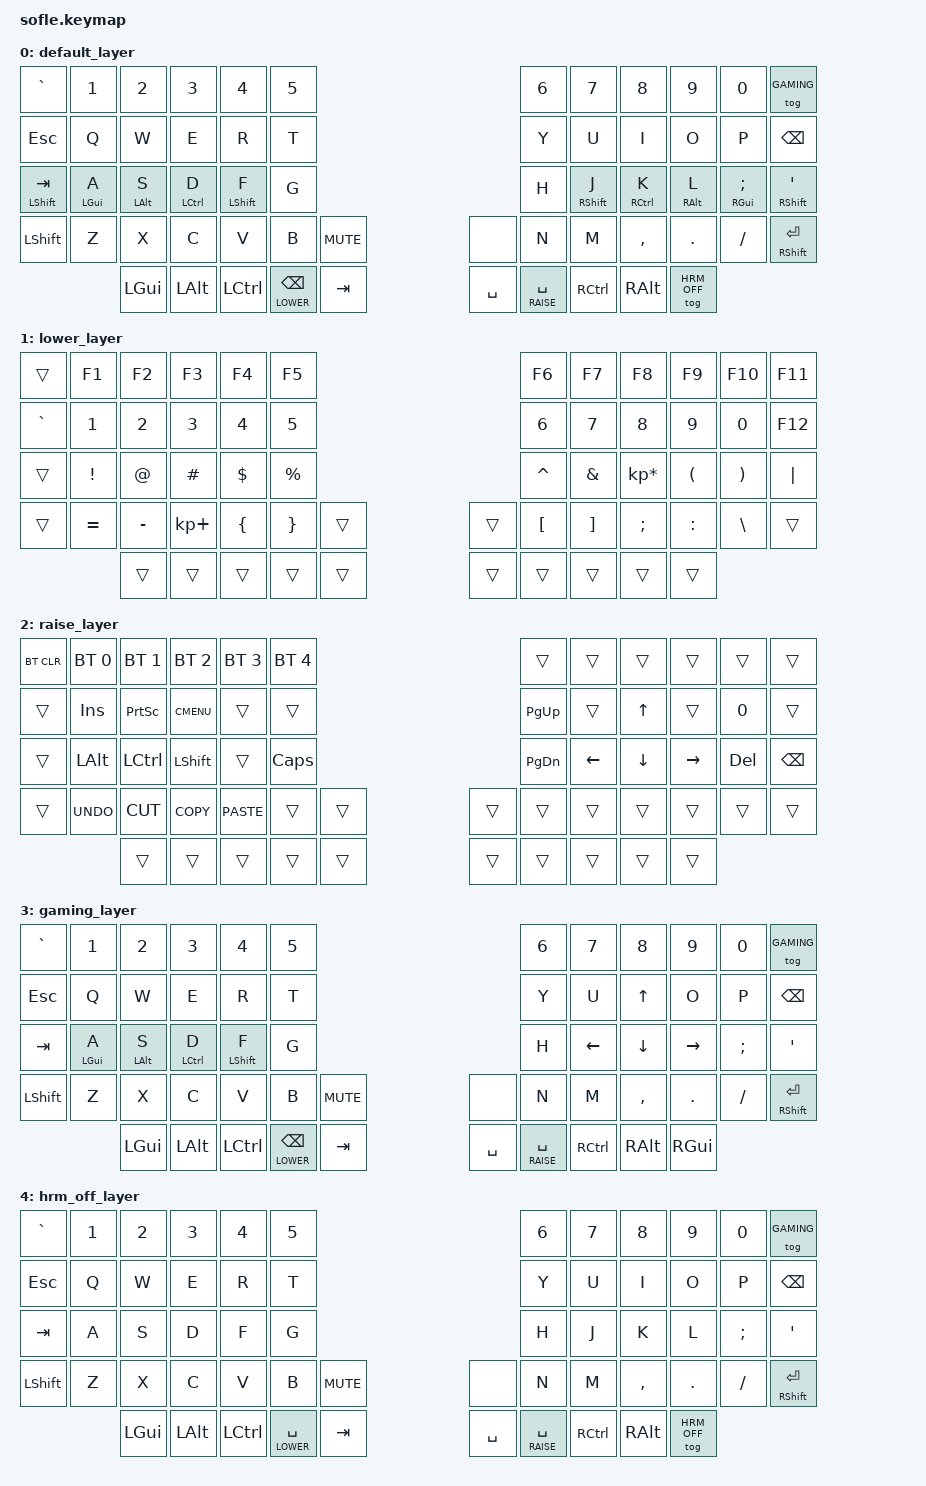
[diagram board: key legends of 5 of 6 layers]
/*
 * Copyright (c) 2020 The ZMK Contributors
 *
 * SPDX-License-Identifier: MIT
 */

#include <behaviors.dtsi>
#include <dt-bindings/zmk/keys.h>
#include <dt-bindings/zmk/bt.h>

#define DEFAULT 0
#define LOWER   1
#define RAISE   2
#define GAMING  3
#define HRM_OFF 4

/ {
    behaviors {
      hm: homerow_mods {
        compatible = "zmk,behavior-hold-tap";
        label = "HOMEROW_MODS";
        #binding-cells = <2>;
        tapping_term_ms = <200>;
        flavor = "tap-preferred";
        bindings = <&kp>, <&kp>;
      };
    };

    conditional_layers {
        compatible = "zmk,conditional-layers";
        tri_layer {
            if-layers = <1 2>;
            then-layer = <5>;
        };
    };
    
    keymap {
        compatible = "zmk,keymap";

        default_layer {
// ------------------------------------------------------------------------------------------------------------
// |  `      |  1   |  2   |  3    |  4    |  5   |                   |  6   |  7    |  8    |  9   |   0   | GAMING|
// |  ESC    |  Q   |  W   |  E    |  R    |  T   |                   |  Y   |  U    |  I    |  O   |   P   | BKSPC |
// |SHFT(TAB)|GUI(A)|ALT(S)|CTRL(D)|SHFT(F)|  G   |                   |  H   |SHFT(J)|CTRL(K)|ALT(L)|GUI(;) |SHFT(')|
// | SHIFT   |  Z   |  X   |  C    |  V    |  B   |  MUTE  |  |       |  N   |  M    |  ,    |  .   |   /   |SHFT(RET)|
//                | GUI  | ALT   | CTRL  | LWR(BKSP)|  TAB |  | SPACE | RSE(SPC) | CTRL  | ALT   |HRM_OFF|
            bindings = <
&kp GRAVE     &kp N1     &kp N2     &kp N3      &kp N4      &kp N5                                      &kp N6          &kp N7       &kp N8      &kp N9     &kp N0        &tog GAMING
&kp ESC       &kp Q      &kp W      &kp E       &kp R       &kp T                                       &kp Y           &kp U        &kp I       &kp O      &kp P         &kp BSPC
&hm LSHFT TAB &hm LGUI A &hm LALT S &hm LCTRL D &hm LSHFT F &kp G                                       &kp H           &hm RSHFT J  &hm RCTRL K &hm RALT L &hm RGUI SEMI &hm RSHFT SQT
&kp LSHFT     &kp Z      &kp X      &kp C       &kp V       &kp B &kp C_MUTE                      &none &kp N           &kp M        &kp COMMA   &kp DOT    &kp FSLH      &mt RSHFT RET
                     &kp LGUI   &kp LALT    &kp LCTRL   &lt LOWER BKSP  &kp TAB           &kp SPACE &lt RAISE SPACE &kp RCTRL    &kp RALT    &tog HRM_OFF
            >;

            sensor-bindings = <&inc_dec_kp C_VOL_UP C_VOL_DN &inc_dec_kp PG_UP PG_DN>;
        };

        lower_layer {
// TODO: Some binds are waiting for shifted keycode support.
// ------------------------------------------------------------------------------------------------------------
// |       |  F1 |  F2 |  F3  |  F4  |  F5  |                   |  F6  |  F7   |  F8   |  F9  |  F10  |  F11  |
// | `     |   1 |   2 |   3  |   4  |   5  |                   |   6  |   7   |   8   |   9  |    0  |  F12  |
// |       |  !  |  @  |  #   |  $   |  %   |                   |  ^   |  &    |  *    |  (   |   )   |   |   |
// |       |  =  |  -  |  +   |  {   |  }   |        |  |       |  [   |  ]    |  ;    |  :   |   \   |       |
//               |     |      |      |      |        |  |       |      |       |       |      |
            bindings = <
&trans    &kp F1    &kp F2    &kp F3      &kp F4    &kp F5                    &kp F6    &kp F7   &kp F8          &kp F9    &kp F10   &kp F11
&kp GRAVE &kp N1    &kp N2    &kp N3      &kp N4    &kp N5                    &kp N6    &kp N7   &kp N8          &kp N9    &kp N0    &kp F12
&trans    &kp EXCL  &kp AT    &kp HASH    &kp DLLR  &kp PRCNT                 &kp CARET &kp AMPS &kp KP_MULTIPLY &kp LPAR  &kp RPAR  &kp PIPE
&trans    &kp EQUAL &kp MINUS &kp KP_PLUS &kp LBRC  &kp RBRC  &trans   &trans &kp LBKT  &kp RBKT &kp SEMI        &kp COLON &kp BSLH  &trans
                    &trans    &trans      &trans    &trans    &trans   &trans &trans    &trans   &trans          &trans
            >;

            sensor-bindings = <&inc_dec_kp C_VOL_UP C_VOL_DN &inc_dec_kp PG_UP PG_DN>;
        };

        raise_layer {
// ------------------------------------------------------------------------------------------------------------
// |BTCLR| BT1  | BT2  |  BT3  |  BT4  |  BT5 |                |      |      |       |      |       |       |
// |     | INS  | PSCR | GUI   |       |      |                | PGUP |      |   ^   |      |       |       |
// |     | ALT  | CTRL | SHIFT |       | CAPS |                | PGDN |   <- |   v   |  ->  |  DEL  | BKSPC |
// |     | UNDO | CUT  | COPY  | PASTE |      |      |  |      |      |      |       |      |       |       |
//              |      |       |       |      |      |  |      |      |      |       |      |
            bindings = <
&bt BT_CLR &bt BT_SEL 0 &bt BT_SEL 1 &bt BT_SEL 2 &bt BT_SEL 3 &bt BT_SEL 4             &trans    &trans    &trans   &trans    &trans  &trans
&trans     &kp INS      &kp PSCRN    &kp K_CMENU  &trans       &trans                   &kp PG_UP &trans    &kp UP   &trans    &kp N0  &trans
&trans     &kp LALT     &kp LCTRL    &kp LSHFT    &trans       &kp CLCK                 &kp PG_DN &kp LEFT  &kp DOWN &kp RIGHT &kp DEL &kp BSPC
&trans     &kp K_UNDO   &kp K_CUT    &kp K_COPY   &kp K_PASTE  &trans  &trans   &trans  &trans    &trans    &trans   &trans    &trans  &trans
                        &trans       &trans       &trans       &trans  &trans   &trans  &trans    &trans    &trans   &trans
            >;

            sensor-bindings = <&inc_dec_kp C_VOL_UP C_VOL_DN &inc_dec_kp PG_UP PG_DN>;
        };

        gaming_layer {
// ------------------------------------------------------------------------------------------------------------
// |  `    |  1   |  2   |  3    |  4    |  5   |                   |  6   |  7    |  8    |  9   |   0   | GAMING|
// |  ESC  |  Q   |  W   |  E    |  R    |  T   |                   |  Y   |  U    |  ^    |  O   |   P   | BKSPC |
// |  TAB  |  A   |  S   |  D    |  F    |  G   |                   |  H   |  <-   |  v    |  ->  |   ;   |   '   |
// | SHIFT |  Z   |  X   |  C    |  V    |  B   |  MUTE  |  |       |  N   |  M    |  ,    |  .   |   /   |SHFT(RET)|
//                | GUI  | ALT   | CTRL  | LWR(BKSP)|  TAB |  | SPACE | RSE(SPC) | CTRL  | ALT   | GUI  |    

            bindings = <
&kp GRAVE &kp N1     &kp N2     &kp N3      &kp N4      &kp N5                                      &kp N6          &kp N7       &kp N8      &kp N9     &kp N0        &tog GAMING
&kp ESC   &kp Q      &kp W      &kp E       &kp R       &kp T                                       &kp Y           &kp U        &kp UP      &kp O      &kp P         &kp BSPC
&kp TAB   &hm LGUI A &hm LALT S &hm LCTRL D &hm LSHFT F &kp G                                       &kp H           &kp LEFT     &kp DOWN    &kp RIGHT  &kp SEMI      &kp SQT
&kp LSHFT &kp Z      &kp X      &kp C       &kp V       &kp B &kp C_MUTE                      &none &kp N           &kp M        &kp COMMA   &kp DOT    &kp FSLH      &mt RSHFT RET
                     &kp LGUI   &kp LALT    &kp LCTRL   &lt LOWER BKSP  &kp TAB           &kp SPACE &lt RAISE SPACE &kp RCTRL    &kp RALT    &kp RGUI
            >;

            sensor-bindings = <&inc_dec_kp C_VOL_UP C_VOL_DN &inc_dec_kp PG_UP PG_DN>;
        };

        hrm_off_layer {
// ------------------------------------------------------------------------------------------------------------
// |  `    |  1   |  2   |  3    |  4    |  5   |                   |  6   |  7    |  8    |  9   |   0   | GAMING|
// |  ESC  |  Q   |  W   |  E    |  R    |  T   |                   |  Y   |  U    |  I    |  O   |   P   | BKSPC |
// |  TAB  |  A   |  S   |  D    |  F    |  G   |                   |  H   |  J    |  K    |  L   |   ;   |   '   |
// | SHIFT |  Z   |  X   |  C    |  V    |  B   |  MUTE  |  |       |  N   |  M    |  ,    |  .   |   /   |SHFT(RET)|
//                | GUI  | ALT   | CTRL  |LWR(SPC)|  TAB |  | SPACE | RSE(SPC) | CTRL  | ALT   | HRM_OFF |
            bindings = <
&kp GRAVE &kp N1     &kp N2     &kp N3      &kp N4      &kp N5                                      &kp N6          &kp N7       &kp N8      &kp N9     &kp N0        &tog GAMING
&kp ESC   &kp Q      &kp W      &kp E       &kp R       &kp T                                       &kp Y           &kp U        &kp I       &kp O      &kp P         &kp BSPC
&kp TAB   &kp A      &kp S      &kp D       &kp  F      &kp G                                       &kp H           &kp J        &kp K       &kp L      &kp SEMI      &kp SQT
&kp LSHFT &kp Z      &kp X      &kp C       &kp V       &kp B &kp C_MUTE                      &none &kp N           &kp M        &kp COMMA   &kp DOT    &kp FSLH      &mt RSHFT RET
                     &kp LGUI   &kp LALT    &kp LCTRL   &lt LOWER SPACE     &kp TAB           &kp SPACE &lt RAISE SPACE &kp RCTRL    &kp RALT    &tog HRM_OFF
            >;

            sensor-bindings = <&inc_dec_kp C_VOL_UP C_VOL_DN &inc_dec_kp PG_UP PG_DN>;
        }; 

        adjust_layer {
// ------------------------------------------------------------------------------------------------------------
// |  `    |  1   |  2   |  3    |  4    |  5   |                   |  6   |  7    |  8    |  9   |   0   | GAMING|
// |  ESC  |  Q   |  W   |  E    |  R    |  T   |                   |  Y   |  U    |  I    |  O   |   P   | BKSPC |
// |  TAB  |  A   |  S   |  D    |  F    |  G   |                   |  H   |  J    |  K    |  L   |   ;   |   '   |
// | SHIFT |  Z   |  X   |  C    |  V    |  B   |  MUTE  |  |       |  N   |  M    |  ,    |  .   |   /   |SHFT(RET)|
//                | GUI  | ALT   | CTRL  | LWR(BKSP)|  TAB |  | SPACE | RSE(SPC) | CTRL  | ALT   | GUI  |
                        bindings = <
   &none           &to  DEFAULT    &to  HRM_OFF    &none           &none &none              &none       &none        &none        &none        &none        &none                        
   &none           &none           &none           &none           &none &none              &none       &none        &none        &none        &none        &none
   &none           &none           &none           &none           &none &none              &none       &none        &none        &none        &none        &none
   &none           &none           &none           &none           &none &none              &none       &none        &none        &none        &none        &none
                                                             &trans      &trans       &trans      &trans        &trans      &trans
            >;

            sensor-bindings = <&inc_dec_kp C_VOL_UP C_VOL_DN &inc_dec_kp PG_UP PG_DN>;
        };       
    };
};
